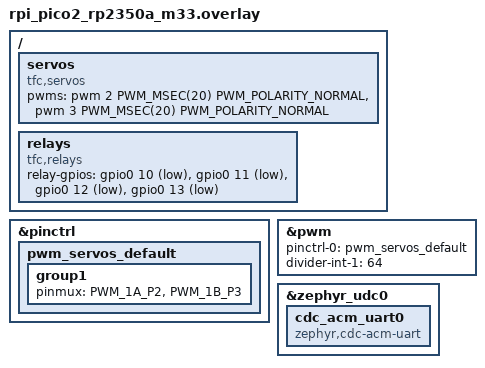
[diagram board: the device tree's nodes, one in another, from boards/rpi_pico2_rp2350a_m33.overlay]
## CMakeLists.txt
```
cmake_minimum_required(VERSION 3.20.0)
find_package(Zephyr REQUIRED HINTS $ENV{ZEPHYR_BASE})
project(tfc_pico LANGUAGES C CXX)

# core/ is consumed as-is: header-only, no heap, no exceptions, no RTTI.
target_include_directories(app PRIVATE ${CMAKE_CURRENT_LIST_DIR}/../../core/include)
target_sources(app PRIVATE src/main.cpp src/usb_init.c)
target_compile_options(app PRIVATE -ffp-contract=off)
```

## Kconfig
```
# SPDX-License-Identifier: MIT
mainmenu "Platform driver and fault injector (Pico 2)"

config TFC_USB_VID
	hex "USB vendor id"
	default 0x1209
	help
	  The pid.codes open vendor id, for a private bench device (its test product id is 0x0001). Zephyr's own vendor id must not be used outside
	  Zephyr's samples. Nothing here is for sale or for the field.

config TFC_USB_PID
	hex "USB product id"
	default 0x0001

config TFC_LINK_TIMEOUT_MS
	int "Nothing from the PC for this long: release every relay (milliseconds)"
	default 2000
	range 200 30000
	help
	  The PC keeps a cut alive by sending it again; if the link goes quiet for this long every node is powered again, whatever time was left on a cut.

config TFC_SERVO_NEUTRAL_US
	int "Servo pulse at level (microseconds)"
	default 1500

config TFC_SERVO_US_PER_DEG_X100
	int "Servo pulse per degree, times 100"
	default 1034
	help
	  The D85MG's 850 to 2350 us over 145 degrees is about 10.34 us per degree (parts sheet row 29).

config TFC_SERVO_X_SIGN
	int "Direction of the tilt-about-X servo (1 or -1)"
	default 1
	range -1 1

config TFC_SERVO_Y_SIGN
	int "Direction of the tilt-about-Y servo (1 or -1)"
	default 1
	range -1 1

config TFC_SERVO_X_TRIM_X100
	int "Mounting offset of the X servo, degrees times 100"
	default 0

config TFC_SERVO_Y_TRIM_X100
	int "Mounting offset of the Y servo, degrees times 100"
	default 0

config TFC_PLATFORM_LIMIT_DEG
	int "Platform travel limit, each plane (degrees)"
	default 45
	range 1 70

config TFC_PLATFORM_RATE_DPS
	int "Platform rate limit (degrees per second)"
	default 300
	range 10 1000

config TFC_WATCHDOG_TIMEOUT_MS
	int "Hardware watchdog timeout (milliseconds)"
	default 100
	range 20 4000

source "Kconfig.zephyr"
```

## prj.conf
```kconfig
CONFIG_CPP=y
CONFIG_STD_CPP17=y
# Flight-code rules (ARCHITECTURE.md section 6): no exceptions, no RTTI, no heap.
CONFIG_CPP_EXCEPTIONS=n
CONFIG_CPP_RTTI=n
CONFIG_REQUIRES_FULL_LIBCPP=y
CONFIG_COMMON_LIBC_MALLOC=n

# The USB serial link to the PC (the new USB device stack)
CONFIG_USB_DEVICE_STACK_NEXT=y
CONFIG_USBD_CDC_ACM_CLASS=y
CONFIG_SERIAL=y
CONFIG_UART_LINE_CTRL=y
CONFIG_CDC_ACM_SERIAL_INITIALIZE_AT_BOOT=n

# Servo pulses, relay lines, the watchdog and the reset cause
CONFIG_PWM=y
CONFIG_GPIO=y
CONFIG_WATCHDOG=y
CONFIG_HWINFO=y

CONFIG_LOG=y
CONFIG_USBD_LOG_LEVEL_ERR=y
CONFIG_UDC_DRIVER_LOG_LEVEL_ERR=y
CONFIG_USBD_CDC_ACM_LOG_LEVEL_OFF=y
CONFIG_MAIN_STACK_SIZE=4096
```

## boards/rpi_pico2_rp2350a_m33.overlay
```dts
/* Platform driver and fault injector on the Pico 2 (docs/design/PICO.md, docs/hardware/HARDWARE_PARTS.md, ADR-026).
 *
 * Servos: GP2 (PWM slice 1, channel A) tilt about X, GP3 (slice 1, channel B) tilt about Y. Both channels of a slice share a period, 20 ms here.
 * The slice clock is divided by 64 so that 20 ms is 46,875 counts (16 bits), a resolution of 0.43 us.
 * Relays: GP10 (node A), GP11 (B), GP12 (C), GP13 (ACT). The ELEGOO module's inputs are active low; each line needs an external pull-up to 3.3 V
 * (SUPERVISOR.md section 4) so that a pin that is not driven (reset, boot, a crashed program) leaves the relay off, which is a powered node
 * (normally-closed contacts). The module's VCC/JD-VCC jumper is removed (docs/hardware/HARDWARE_PARTS.md section 7, item 7).
 */
#include <zephyr/dt-bindings/gpio/gpio.h>
#include <zephyr/dt-bindings/pwm/pwm.h>
#include <zephyr/dt-bindings/pinctrl/rpi-pico-rp2350a-pinctrl.h>

&pinctrl {
	pwm_servos_default: pwm_servos_default {
		group1 {
			pinmux = <PWM_1A_P2>, <PWM_1B_P3>;
		};
	};
};

&pwm {
	pinctrl-0 = <&pwm_servos_default>;
	pinctrl-names = "default";
	divider-int-1 = <64>;
	status = "okay";
};

/ {
	servos: servos {
		compatible = "tfc,servos";
		pwms = <&pwm 2 PWM_MSEC(20) PWM_POLARITY_NORMAL>,
		       <&pwm 3 PWM_MSEC(20) PWM_POLARITY_NORMAL>;
	};

	relays: relays {
		compatible = "tfc,relays";
		relay-gpios = <&gpio0 10 GPIO_ACTIVE_LOW>,
			      <&gpio0 11 GPIO_ACTIVE_LOW>,
			      <&gpio0 12 GPIO_ACTIVE_LOW>,
			      <&gpio0 13 GPIO_ACTIVE_LOW>;
	};
};

/* The USB serial port to the PC: one CDC ACM function on the board's USB device controller. */
&zephyr_udc0 {
	cdc_acm_uart0 {
		compatible = "zephyr,cdc-acm-uart";
	};
};
```

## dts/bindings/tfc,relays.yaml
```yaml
# SPDX-License-Identifier: MIT
description: The fault injector's four relay inputs (nodes A, B, C and ACT), active low, with external pull-ups to 3.3 V so that a floating pin means "off"
compatible: "tfc,relays"
properties:
  relay-gpios:
    type: phandle-array
    required: true
```

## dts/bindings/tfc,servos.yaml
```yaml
# SPDX-License-Identifier: MIT
description: The platform's two servo signals, one PWM channel each (tilt about X first, then about Y)
compatible: "tfc,servos"
properties:
  pwms:
    type: phandle-array
    required: true
```

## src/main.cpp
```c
// SPDX-License-Identifier: MIT
// The platform driver and fault injector on the Pico 2 (docs/design/PICO.md; ADR-026): the board's side of tfc::PicoApp (core/include/tfc/pico_app.hpp, tested on the host with a fake
// board). Every 10 ms the loop in the core:
//   - the bytes from the PC (USB serial) go through the link parser: a platform command goes to the platform driver, a relay command to the injector, a ping asks for a
//     status; a frame that does not check is dropped;
//   - the platform driver applies its limit, rate limit and timeout (TFC-PLAT-001, 002, 004) and the servo pulses follow: two PWM channels at 50 Hz;
//   - the injector's cuts run down by themselves, and if nothing has come from the PC for the link timeout every relay is released;
//   - a status (the output, the flags, the relays, the command age) goes back to the PC;
//   - the hardware watchdog is fed.
// The relays are active low with external pull-ups: a pin that is not driven (reset, boot, a crash) is a relay off, which is a powered node. Up to the first command the
// servos are held at level. None of this has been run on a board yet.
//
// Include core/ (and so the C++ standard library) BEFORE Zephyr headers: Zephyr defines an `__unused` macro that breaks a glibc header.
#include <array>
#include <cstdint>

#include "tfc/pico_app.hpp"
#include "tfc/resetlog.hpp"

#include "usb_init.h"

#include <zephyr/device.h>
#include <zephyr/devicetree.h>
#include <zephyr/drivers/gpio.h>
#include <zephyr/drivers/hwinfo.h>
#include <zephyr/drivers/pwm.h>
#include <zephyr/drivers/uart.h>
#include <zephyr/drivers/watchdog.h>
#include <zephyr/kernel.h>
#include <zephyr/usb/usbd.h>

namespace {

const struct device* const g_uart = DEVICE_DT_GET_ONE(zephyr_cdc_acm_uart);
const struct pwm_dt_spec g_servo[2] = {PWM_DT_SPEC_GET_BY_IDX(DT_NODELABEL(servos), 0), PWM_DT_SPEC_GET_BY_IDX(DT_NODELABEL(servos), 1)};
const struct gpio_dt_spec g_relays[tfc::kInjectorChannels] = {
    GPIO_DT_SPEC_GET_BY_IDX(DT_NODELABEL(relays), relay_gpios, 0), GPIO_DT_SPEC_GET_BY_IDX(DT_NODELABEL(relays), relay_gpios, 1),
    GPIO_DT_SPEC_GET_BY_IDX(DT_NODELABEL(relays), relay_gpios, 2), GPIO_DT_SPEC_GET_BY_IDX(DT_NODELABEL(relays), relay_gpios, 3)};

void usb_message(struct usbd_context* const ctx, const struct usbd_msg* msg) {
  if (usbd_can_detect_vbus(ctx)) {
    if (msg->type == USBD_MSG_VBUS_READY) {
      (void)usbd_enable(ctx);
    } else if (msg->type == USBD_MSG_VBUS_REMOVED) {
      (void)usbd_disable(ctx);
    }
  }
}

tfc::ResetCause reset_cause() {
  uint32_t flags = 0U;
  if (hwinfo_get_reset_cause(&flags) != 0) {
    return tfc::ResetCause::Unknown;
  }
  (void)hwinfo_clear_reset_cause();
  if ((flags & RESET_POR) != 0U) {
    return tfc::ResetCause::PowerOn;
  }
  if ((flags & RESET_WATCHDOG) != 0U) {
    return tfc::ResetCause::Watchdog;
  }
  if ((flags & RESET_BROWNOUT) != 0U) {
    return tfc::ResetCause::Brownout;
  }
  return tfc::ResetCause::Unknown;
}

// The board behind tfc::PicoApp's interface.
class Board {
 public:
  Board(const struct device* wdt, int wdt_channel) : wdt_(wdt), wdt_channel_(wdt_channel) {}

  bool read_byte(uint8_t& b) { return uart_poll_in(g_uart, &b) == 0; }
  void write(const uint8_t* data, std::size_t n) {
    (void)uart_fifo_fill(g_uart, data, static_cast<int>(n));  // a short write is a lost status: the next one follows in 20 ms
  }
  void set_servo_us(unsigned axis, float us) { (void)pwm_set_dt(&g_servo[axis], PWM_USEC(20000U), PWM_USEC(static_cast<uint32_t>(us + 0.5F))); }
  void set_relays(uint8_t energised) {
    for (unsigned i = 0; i < tfc::kInjectorChannels; ++i) {
      (void)gpio_pin_set_dt(&g_relays[i], ((energised >> i) & 1U) != 0U ? 1 : 0);  // the devicetree says active low
    }
  }
  void feed_watchdog() {
    if (wdt_channel_ >= 0) {
      (void)wdt_feed(wdt_, wdt_channel_);
    }
  }

 private:
  const struct device* wdt_;
  int wdt_channel_;
};

}  // namespace

int main() {
  // The relays first: every output is configured "inactive" (the pin high, the relay off, the node powered) before anything else can go wrong.
  for (const struct gpio_dt_spec& r : g_relays) {
    if (gpio_is_ready_dt(&r)) {
      (void)gpio_pin_configure_dt(&r, GPIO_OUTPUT_INACTIVE);
    }
  }
  const tfc::ResetCause cause = reset_cause();
  struct usbd_context* usb = tfc_usbd_init(usb_message);
  if (usb != nullptr && !usbd_can_detect_vbus(usb)) {
    (void)usbd_enable(usb);
  }
  if (!device_is_ready(g_uart) || !pwm_is_ready_dt(&g_servo[0]) || !pwm_is_ready_dt(&g_servo[1])) {
    return 1;
  }

  tfc::PicoAppConfig cfg;
  cfg.platform.limit_deg = static_cast<float>(CONFIG_TFC_PLATFORM_LIMIT_DEG);
  cfg.platform.rate_limit_dps = static_cast<float>(CONFIG_TFC_PLATFORM_RATE_DPS);
  cfg.link_timeout_ms = static_cast<uint32_t>(CONFIG_TFC_LINK_TIMEOUT_MS);
  cfg.after_watchdog_reset = cause == tfc::ResetCause::Watchdog;
  cfg.servo_x.neutral_us = static_cast<float>(CONFIG_TFC_SERVO_NEUTRAL_US);
  cfg.servo_x.us_per_deg = static_cast<float>(CONFIG_TFC_SERVO_US_PER_DEG_X100) * 0.01F;
  cfg.servo_x.sign = static_cast<float>(CONFIG_TFC_SERVO_X_SIGN);
  cfg.servo_x.trim_deg = static_cast<float>(CONFIG_TFC_SERVO_X_TRIM_X100) * 0.01F;
  cfg.servo_y = cfg.servo_x;
  cfg.servo_y.sign = static_cast<float>(CONFIG_TFC_SERVO_Y_SIGN);
  cfg.servo_y.trim_deg = static_cast<float>(CONFIG_TFC_SERVO_Y_TRIM_X100) * 0.01F;

  const struct device* const wdt = DEVICE_DT_GET(DT_ALIAS(watchdog0));
  int wdt_channel = -1;
  if (device_is_ready(wdt)) {
    wdt_timeout_cfg wcfg{};
    wcfg.flags = WDT_FLAG_RESET_SOC;
    wcfg.window.min = 0U;
    wcfg.window.max = CONFIG_TFC_WATCHDOG_TIMEOUT_MS;
    wdt_channel = wdt_install_timeout(wdt, &wcfg);
    if (wdt_channel >= 0 && wdt_setup(wdt, WDT_OPT_PAUSE_HALTED_BY_DBG) != 0) {
      wdt_channel = -1;
    }
  }

  Board board(wdt, wdt_channel);
  tfc::PicoApp<Board> app(board, cfg);
  app.boot();  // level, and every node powered, before the first byte is read

  int64_t next = k_uptime_get() + cfg.period_ms;
  for (;;) {
    app.step();
    const int64_t now = k_uptime_get();
    if (next > now) {
      k_msleep(static_cast<int32_t>(next - now));
    }
    next += cfg.period_ms;
  }
}
```

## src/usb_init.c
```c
/* SPDX-License-Identifier: MIT
 *
 * The USB device description for the Pico: one CDC ACM serial port. Written against Zephyr's documented USB device (next) API; Zephyr's own sample helper is
 * not used because its options are limited to the samples in Zephyr's tree.
 */
#include "usb_init.h"

#include <zephyr/device.h>
#include <zephyr/kernel.h>
#include <zephyr/logging/log.h>
#include <zephyr/usb/usbd.h>

LOG_MODULE_REGISTER(tfc_usb, LOG_LEVEL_ERR);

USBD_DEVICE_DEFINE(tfc_usbd, DEVICE_DT_GET(DT_NODELABEL(zephyr_udc0)), CONFIG_TFC_USB_VID, CONFIG_TFC_USB_PID);

USBD_DESC_LANG_DEFINE(tfc_lang);
USBD_DESC_MANUFACTURER_DEFINE(tfc_mfr, "Triplex FC bench");
USBD_DESC_PRODUCT_DEFINE(tfc_product, "Platform driver and fault injector");
USBD_DESC_SERIAL_NUMBER_DEFINE(tfc_sn);

USBD_DESC_CONFIG_DEFINE(tfc_fs_cfg_desc, "FS Configuration");
USBD_CONFIGURATION_DEFINE(tfc_fs_config, 0 /* bus powered, no remote wakeup */, 50 /* 100 mA, in 2 mA units */, &tfc_fs_cfg_desc);

struct usbd_context *tfc_usbd_init(usbd_msg_cb_t msg_cb)
{
	if (usbd_add_descriptor(&tfc_usbd, &tfc_lang) || usbd_add_descriptor(&tfc_usbd, &tfc_mfr) || usbd_add_descriptor(&tfc_usbd, &tfc_product) ||
	    usbd_add_descriptor(&tfc_usbd, &tfc_sn)) {
		LOG_ERR("cannot add the string descriptors");
		return NULL;
	}
	if (usbd_add_configuration(&tfc_usbd, USBD_SPEED_FS, &tfc_fs_config)) {
		LOG_ERR("cannot add the configuration");
		return NULL;
	}
	if (usbd_register_all_classes(&tfc_usbd, USBD_SPEED_FS, 1, NULL)) {
		LOG_ERR("cannot register the classes");
		return NULL;
	}
	/* a class with more than one interface uses an Interface Association Descriptor: miscellaneous device, common class */
	usbd_device_set_code_triple(&tfc_usbd, USBD_SPEED_FS, USB_BCC_MISCELLANEOUS, 0x02, 0x01);
	usbd_self_powered(&tfc_usbd, false);
	if (msg_cb != NULL && usbd_msg_register_cb(&tfc_usbd, msg_cb)) {
		LOG_ERR("cannot register the message callback");
		return NULL;
	}
	if (usbd_init(&tfc_usbd)) {
		LOG_ERR("cannot initialise the USB device");
		return NULL;
	}
	return &tfc_usbd;
}
```

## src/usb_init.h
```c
/* SPDX-License-Identifier: MIT */
#ifndef TFC_PICO_USB_INIT_H
#define TFC_PICO_USB_INIT_H

#include <zephyr/usb/usbd.h>

#ifdef __cplusplus
extern "C" {
#endif

/* Describe the device (one CDC ACM serial port, full speed, bus powered), register `msg_cb`, and initialise the USB device stack. Call usbd_enable() on the result
 * (or wait for VBUS if usbd_can_detect_vbus()). NULL if anything failed. */
struct usbd_context *tfc_usbd_init(usbd_msg_cb_t msg_cb);

#ifdef __cplusplus
}
#endif

#endif
```
